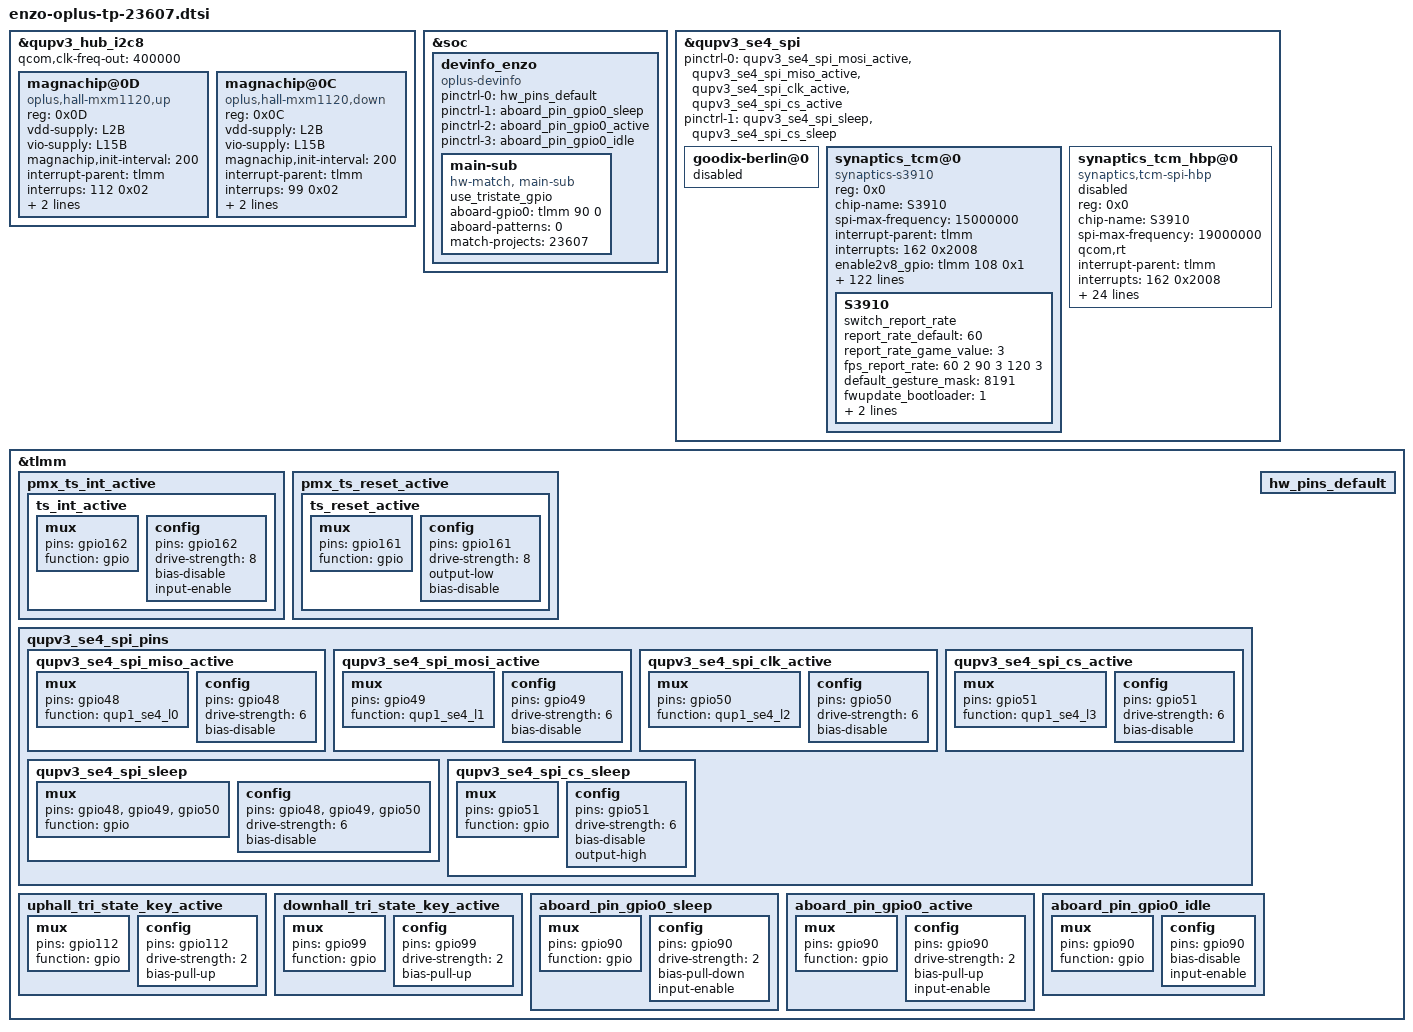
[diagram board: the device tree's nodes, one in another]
&qupv3_hub_i2c8 {
	status = "ok";
	qcom,clk-freq-out = <400000>;
	/delete-node/ magnachip@0D;
	/delete-node/ magnachip@0C;
	/delete-node/ ist8801@19;
	/delete-node/ ist8801@18;

	magnachip@0D {
		compatible = "oplus,hall-mxm1120,up";
		reg = <0x0D>;
		vdd-supply = <&L2B>;
		vio-supply = <&L15B>;
		magnachip,init-interval = <200>;
		interrupt-parent = <&tlmm>;
		interrups = <112 0x02>;
		dhall,irq-gpio = <&tlmm 112 0x2008>;
		pinctrl-names = "uphall_tri_state_key_active";
		pinctrl-0 = <&uphall_tri_state_key_active>;
	};

	magnachip@0C {
		compatible = "oplus,hall-mxm1120,down";
		reg = <0x0C>;
		vdd-supply = <&L2B>;
		vio-supply = <&L15B>;
		magnachip,init-interval = <200>;
		interrupt-parent = <&tlmm>;
		interrups = <99 0x02>;
		dhall,irq-gpio = <&tlmm 99 0x2008>;
		pinctrl-names = "downhall_tri_state_key_active";
		pinctrl-0 = <&downhall_tri_state_key_active>;
	};
};

&soc {

	devinfo_enzo {
		compatible = "oplus-devinfo";
		pinctrl-names = "default", "sleep", "active", "idle";
		pinctrl-0 = <&hw_pins_default>;
		pinctrl-1 = <&aboard_pin_gpio0_sleep>;
		pinctrl-2 = <&aboard_pin_gpio0_active>;
		pinctrl-3 = <&aboard_pin_gpio0_idle>;

		main-sub {
			compatible = "hw-match, main-sub";
			use_tristate_gpio;
			aboard-gpio0 = <&tlmm 90 0>;
			aboard-patterns = <0>;	/*0[high-resistance] 1[pull-down] 2[pull-up]*/
			/*main board*/
			match-projects = <23607>;
		};
	};
};

&qupv3_se4_spi{
	/delete-property/ pinctrl-0;
	/delete-property/ pinctrl-1;
	pinctrl-0 = <&qupv3_se4_spi_mosi_active>, <&qupv3_se4_spi_miso_active>,
				<&qupv3_se4_spi_clk_active>, <&qupv3_se4_spi_cs_active>;
	pinctrl-1 = <&qupv3_se4_spi_sleep>, <&qupv3_se4_spi_cs_sleep>;
};

&qupv3_se4_spi {
	status = "ok";

	goodix-berlin@0 {
		status = "disabled";
	};

	synaptics_tcm@0{
		compatible = "synaptics-s3910";
		reg = <0x0>;
		chip-name = "S3910";
		status = "ok";
		spi-max-frequency = <15000000>;

		/* Interrupt && Irq-gpio */
		interrupt-parent = <&tlmm>;
		interrupts = <162 0x2008>;

		/* Power Config */
		enable2v8_gpio = <&tlmm 108 0x1>;
		//enable1v8_gpio = <&tlmm 97 0x1>;
		//vdd_2v8-supply = <&L14B>;
		vcc_1v8-supply = <&L4B>;
		vdd_2v8_volt = <3008000>;

		/* Other HW Resource */
		irq-gpio = <&tlmm 162 0x2008>;
		reset-gpio = <&tlmm 161 0x1>;
		pinctrl-names = "default";
		pinctrl-0 = <&ts_int_active &ts_reset_active>;

		touchpanel,max-num-support = <10>;
		touchpanel,tx-rx-num = <17 38>;
		earsense,tx-rx-num = <16 36>;
		touchpanel,panel-coords = <12640 27800>;
		touchpanel,display-coords = <1264 2780>;
		touchpanel,touchmajor-limit = <128 216>;
		touchpanel,elimination-range = <20 200 200>;
		touchpanel,int-mode = <1>; /*0: interrupt and disable, 1:interrupt and not disable*/
		touchpanel,curved-size = <45>;
		touchpanel,smooth-level = <0 1 2 4 7 9>;
		touchpanel,smooth-level-charging = <0 2 4 7 8 9>;
		touchpanel,sensitive-level = <0 70 55 40 25 10>;
		touchpanel,single-optimized-time = <8>;
		touchpanel,high-frame-rate-time = <60>;

		prevention,curved_screen_V2;
		prevention,grip_disable_level = <6>;
		prevention,updelay_time_ms = <20>;
		prevention,makeup_cnt_weight = <4 1 2 2 2>;
		prevention,large_corner_range = <1400 3400>;
		prevention,large_corner_judge_condition = <500 400 1170 7 7>;
		prevention,trx_reject_condition = <9 8 8>;
		prevention,trx_strict_reject_condition = <8 7 7>;
		prevention,large_judge_time_ms = <500 50 30>;
		prevention,large_exit_condition = <8 8 2>;
		prevention,single_channel_width = <375 375>;
		prevention,normal_tap_condition = <10 350>;
		prevention,long_edge_condition = <179 90 120 80>;
		prevention,long_strict_edge_condition = <160 60>;
		prevention,long_fingerhold_condition = <70 6 4 4>;
		prevention,short_edge_condition = <179 90 120 80>;
		prevention,short_strict_edge_condition = <160 60>;
		prevention,large_strict_exit_condition = <6 6>;
		prevention,top_corner_config = <585 1738 562>;
		prevention,edge_swipe_config = <352 1390>;

		prevention,curved_screen_V4;
		prevention,long_eliminate_point_type = <2 12640 9270 352 27800 300 1>;
		prevention,long_fingerhold_condition2 = <714 2000 0 0>;
		prevention,top_corner_config2 =<3 80 375 702 0>;
		prevention,hor_long_top_corner_config =<702 2317 0 0>;
		prevention,top_middle_config =<12640 1158 1158 0>;
		prevention,corner_eliminate_point_type =<0 1404 2780 1>;
		prevention,finger_hold_differ_size = <1 0 352 300>;
		prevention,finger_hold_max_rx_exit_distance = <5 352 2317>;
		prevention,max_rx_exit_distance = <1 5 120 352 2317>;
		prevention,dynamic_finger_hold_exit_distance = <1 352 2317 410>;
		prevention,edge_sliding_matched_support = <1 200 3 1>;

		//grip v4.2 reclining mode
		prevention,reclining_mode_support = <1>;
		prevention,long_eliminate_point_type_recli = <2 12640 9270 352 27800 500 1>;
		prevention,finger_hold_differ_size_recli = <1 0 352 300>;
		prevention,finger_hold_max_rx_exit_distance_recli = <5 352 2317>;
		prevention,max_rx_exit_distance_recli = <1 5 120 352 2317>;
		prevention,dynamic_finger_hold_exit_distance_recli = <1 352 2317 410>;
		prevention,edge_sliding_matched_support_recli = <1 150 3 0>;
		prevention,long_edge_condition_recli = <179 90 120 80>;

		end_stretch_value = <480 250 16 16>;
		touchpanel,tp_ic_type = <2>;
		panel_type = <7 7 3 7 3 3 3 3 3>;
		// type of tp_dev ,TP-SAMSUNG = 8;
		//firmware_name = "AA545";
		platform_support_project = <23607>;
		platform_support_project_dir = <23607>;
		platform_support_project_commandline = "mdss_dsi_panel_enzo_boe_ili7838e_1264_2780_dsc_cmd","mdss_dsi_panel_enzo_boe_ili7838e_high_pre_dsc_cmd",
		"mdss_dsi_panel_enzo_boe_ili7838e_evt_dsc_cmd","mdss_dsi_panel_enzo_boe_ili7838e_evt_old_dsc_cmd","mdss_dsi_panel_enzo_boe_ili7838e_dvt_dsc_cmd",
		"mdss_dsi_panel_enzo_boe_ili7838e_dvt_low_dsc_cmd","mdss_dsi_panel_enzo_boe_ili7838e_pvt_dsc_cmd","mdss_dsi_panel_enzo_boe_ili7838e_pre_pvt_dsc_cmd","mdss_dsi_panel_enzo_boe_ili7838e_pvt_bd_dsc_cmd";

		/* SW Support Feature Control */
		black_gesture_support;
		//fw_edge_limit_support;
		pressure_report_support;
		charger_pump_support;
		game_switch_support;
		smart_gesture_support;
		fw_update_app_support;
		fingerprint_underscreen_support;
		freq_hop_simulate_support;
		report_flow_unlock_support;
		screenoff_fingerprint_info_support;
		irq_need_dev_resume_ok;
		//firmware_in_dts;
		enable_point_auto_change;
		report_rate_white_list_support;
		kernel_grip_support;
		//grip_no_driver_support;
		health_monitor_support;
		black_gesture_indep_support;
		algorithm_support;
		spi_port_support;
		exception_upload_support;
		sportify_aod_gesture_support;
		glove_mode_support;
		fingerprint_not_report_in_suspend;
		snr_read_support;
		palm_to_sleep_support;
		skip_reinit_device_support;
		tp_data_record_support;
		edge_pull_out_support;
		diaphragm_touch_support;

		/*
		 *Virtual Key Config:
		 *1:touchpanel,button-type: <virtualkey_type  supportted_button-map>
		 *virtualkey_type:
		 *Type 1: using board_properties
		 *Type 2: using same IC (button zone&& touch zone are seprate)
		 *Type 3: using diffrent IC (button zone&& touch zone are seprate)
		 *Type 4: No need of virtual key process
		 *supportted_button-map:select|menu|home|back
		 *
		 *2:touchpanel,button-map
		 *type (X1,Y1)(X2,Y2)(X3,Y3)(Width_X,Hight_Y)--Only when button-type is 0
		 */
		touchpanel,button-type = <4>;
		touchpanel.button-TRx = <0 0>;

		S3910 {
			switch_report_rate;
			report_rate_default = <60>;
			report_rate_game_value = <3>;
			fps_report_rate = <60 2 90 3 120 3>;//1:360Hz 2:125Hz 3:240Hz
			default_gesture_mask = <8191>;
			fwupdate_bootloader = <1>;
			normal_config_version = <2>;
			extreme_game_report_rate = <360>;//360Hz
		};
	};

	synaptics_tcm_hbp@0{
		compatible = "synaptics,tcm-spi-hbp";
		reg = <0x0>;
		chip-name = "S3910";
		status = "disabled";
		spi-max-frequency = <19000000>;
		qcom,rt;

		/* Interrupt && Irq-gpio */
		interrupt-parent = <&tlmm>;
		interrupts = <162 0x2008>;

		/* Power Config */
		synaptics,avdd-gpio = <&tlmm 108 0x1>;
		vdd-supply = <&L4B>;
		synaptics,vdd-name = "vdd";

		/* Other HW Resource */
		synaptics,irq-gpio = <&tlmm 162 0x2008>;
		synaptics,reset-gpio = <&tlmm 161 0x1>;
		pinctrl-names = "default";
		pinctrl-0 = <&ts_int_active &ts_reset_active>;

		touchpanel,panel-coords = <12640 27800>;
		touchpanel,tx-rx-num = <17 38>;
		//touchpanel,tp_ic_type = <2>;
		panel_type = <7 7 3>;
		// type of tp_dev ,TP-SAMSUNG = 8;
		//firmware_name = "AA545";
		platform_support_project = <23607>;
		platform_support_project_dir = <23607>;
		platform_support_project_commandline = "mdss_dsi_panel_enzo_boe_ili7838e_1264_2780_dsc_cmd","mdss_dsi_panel_enzo_boe_ili7838e_high_pre_dsc_cmd",
		"mdss_dsi_panel_enzo_boe_ili7838e_evt_dsc_cmd";

		synaptics,power-on-state = <1>;
		synaptics,power-delay-ms = <200>;
		synaptics,irq-on-state = <0>;
		synaptics,reset-on-state = <0>;
		synaptics,reset-active-ms = <10>;
		synaptics,reset-delay-ms = <80>;
		synaptics,spi-mode = <0>;
		synaptics,spi-byte-delay-us = <0>;
		synaptics,spi-block-delay-us = <0>;
	};
};

&tlmm {
	pmx_ts_int_active {
		ts_int_active: ts_int_active {
			mux {
				pins = "gpio162";
				function = "gpio";
			};

			config {
				pins = "gpio162";
				drive-strength = <8>;
				bias-disable;
				input-enable;
			};
		};
	};

	pmx_ts_reset_active {
		ts_reset_active: ts_reset_active {
			mux {
				pins = "gpio161";
				function = "gpio";
			};

			config {
				pins = "gpio161";
				drive-strength = <8>;
				output-low;
				bias-disable;
			};
		};
	};

	qupv3_se4_spi_pins: qupv3_se4_spi_pins {
		qupv3_se4_spi_miso_active: qupv3_se4_spi_miso_active {
			mux {
				pins = "gpio48";
				function = "qup1_se4_l0";
			};

			config {
				pins = "gpio48";
				drive-strength = <6>;
				bias-disable;
			};
		};

		qupv3_se4_spi_mosi_active: qupv3_se4_spi_mosi_active {
			mux {
				pins = "gpio49";
				function = "qup1_se4_l1";
			};

			config {
				pins = "gpio49";
				drive-strength = <6>;
				bias-disable;
			};
		};

		qupv3_se4_spi_clk_active: qupv3_se4_spi_clk_active {
			mux {
				pins = "gpio50";
				function = "qup1_se4_l2";
			};

			config {
				pins = "gpio50";
				drive-strength = <6>;
				bias-disable;
			};
		};

		qupv3_se4_spi_cs_active: qupv3_se4_spi_cs_active {
			mux {
				pins = "gpio51";
				function = "qup1_se4_l3";
			};

			config {
				pins = "gpio51";
				drive-strength = <6>;
				bias-disable;
			};
		};

		qupv3_se4_spi_sleep: qupv3_se4_spi_sleep {
			mux {
				pins = "gpio48", "gpio49",
						"gpio50";
				function = "gpio";
			};

			config {
				pins = "gpio48", "gpio49",
						"gpio50";
				drive-strength = <6>;
				bias-disable;
			};
		};

		qupv3_se4_spi_cs_sleep: qupv3_se4_spi_cs_sleep {
			mux {
				pins = "gpio51";
				function = "gpio";
			};

			config {
				pins = "gpio51";
				drive-strength = <6>;
				bias-disable;
				output-high;
			};
		};
	};

	uphall_tri_state_key_active: uphall_tri_state_key_active {
		mux {
			pins = "gpio112";
			function = "gpio";
		};
		config {
			pins = "gpio112";
			drive-strength = <2>;
			bias-pull-up;
		};
	};

	downhall_tri_state_key_active: downhall_tri_state_key_active {
		mux {
			pins = "gpio99";
			function = "gpio";
		};
		config {
			pins = "gpio99";
			drive-strength = <2>;
			bias-pull-up;
		};
	};

	hw_pins_default:hw_pins_default {
	};
	aboard_pin_gpio0_sleep:aboard_pin_gpio0_sleep {
		mux {
			pins = "gpio90";
			function = "gpio";
		};
		config {
			pins = "gpio90";
			drive-strength = <2>;
			bias-pull-down;
			input-enable;
		};
	};

	aboard_pin_gpio0_active:aboard_pin_gpio0_active {
		mux {
			pins = "gpio90";
			function = "gpio";
		};
		config {
			pins = "gpio90";
			drive-strength = <2>;
			bias-pull-up;
			input-enable;
		};
	};

	aboard_pin_gpio0_idle:aboard_pin_gpio0_idle {
		mux {
			pins = "gpio90";
			function = "gpio";
		};
		config {
			pins = "gpio90";
			bias-disable;
			input-enable;
		};
	};
};
